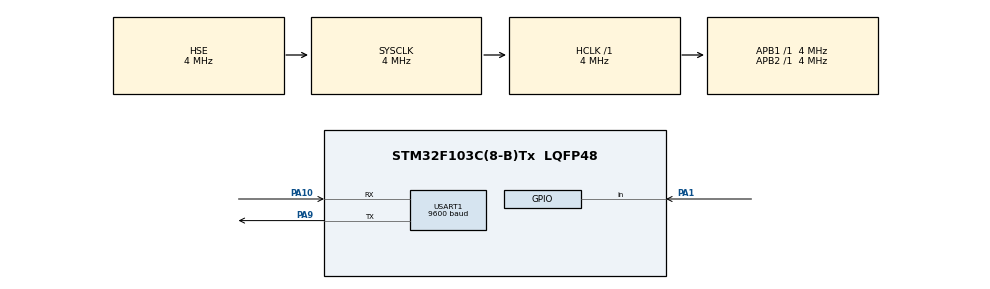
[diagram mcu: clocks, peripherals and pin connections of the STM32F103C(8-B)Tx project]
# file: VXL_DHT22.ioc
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Mcu.Family=STM32F1
Mcu.Name=STM32F103C(8-B)Tx
Mcu.Package=LQFP48
NVIC.PriorityGroup=NVIC_PRIORITYGROUP_4
PA1.GPIO_PuPd=GPIO_PULLUP
PA1.Signal=GPIO_Input
PA10.Mode=Asynchronous
PA10.Signal=USART1_RX
PA13.Mode=Serial_Wire
PA13.Signal=SYS_JTMS-SWDIO
PA14.Mode=Serial_Wire
PA14.Signal=SYS_JTCK-SWCLK
PA9.Mode=Asynchronous
PA9.Signal=USART1_TX
PD0-OSC_IN.Mode=HSE-External-Oscillator
PD0-OSC_IN.Signal=RCC_OSC_IN
PD1-OSC_OUT.Mode=HSE-External-Oscillator
PD1-OSC_OUT.Signal=RCC_OSC_OUT
ProjectManager.HeapSize=0x200
ProjectManager.StackSize=0x400
ProjectManager.TargetToolchain=MDK-ARM V5.32
RCC.AHBFreq_Value=4000000
RCC.APB1Freq_Value=4000000
RCC.APB1TimFreq_Value=4000000
RCC.APB2Freq_Value=4000000
RCC.APB2TimFreq_Value=4000000
RCC.HCLKFreq_Value=4000000
RCC.HSE_VALUE=4000000
RCC.SYSCLKFreq_VALUE=4000000
RCC.SYSCLKSource=RCC_SYSCLKSOURCE_HSE
USART1.BaudRate=9600
USART1.VirtualMode=VM_ASYNC
VP_TIM1_VS_ClockSourceINT.Mode=Internal
board=custom

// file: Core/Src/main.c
/* USER CODE BEGIN Header */
/**
  ******************************************************************************
  * @file           : main.c
  * @brief          : Main program body
  ******************************************************************************
  * @attention
  *
  * Copyright (c) 2023 STMicroelectronics.
  * All rights reserved.
  *
  * This software is licensed under terms that can be found in the LICENSE file
  * in the root directory of this software component.
  * If no LICENSE file comes with this software, it is provided AS-IS.
  *
  ******************************************************************************
  */
/* USER CODE END Header */
#include "main.h"

/* USER CODE BEGIN Includes */
#include <stdio.h>
/*struct __FILE
{
  int handle;
};*/
/* USER CODE END Includes */

TIM_HandleTypeDef htim1;

UART_HandleTypeDef huart1;

/* USER CODE BEGIN PV */
FILE __stdout;
int fputc(int ch, FILE *f)
{
  HAL_UART_Transmit(&huart1,(uint8_t *)&ch,1,HAL_MAX_DELAY);
  return ch;
}
/* USER CODE END PV */

void SystemClock_Config(void);
static void MX_GPIO_Init(void);
static void MX_TIM1_Init(void);
static void MX_USART1_UART_Init(void);

/* USER CODE BEGIN 0 */
uint8_t OneWire_ReadBit(void) {
	#define DELAY50US  200
	while(HAL_GPIO_ReadPin(GPIOA,GPIO_PIN_1)==0);
	__HAL_TIM_SET_COUNTER(&htim1,0);
	while(HAL_GPIO_ReadPin(GPIOA,GPIO_PIN_1)!=0);
	if (__HAL_TIM_GET_COUNTER(&htim1) > DELAY50US)
		return 1;
	else
		return 0;
}

/* USER CODE END 0 */

int main(void)
{

  /* MCU Configuration--------------------------------------------------------*/

  /* Reset of all peripherals, Initializes the Flash interface and the Systick. */
  HAL_Init();

  /* Configure the system clock */
  SystemClock_Config();

  /* Initialize all configured peripherals */
  MX_GPIO_Init();
  MX_TIM1_Init();
  MX_USART1_UART_Init();
  /* USER CODE BEGIN 2 */
	HAL_TIM_Base_Start(&htim1);
	GPIO_InitTypeDef GPIO_InitStruct = {0};
  /* USER CODE END 2 */

  /* Infinite loop */
  while (1)
  {
		/*Configure GPIO pin : PA1 */ // pull_up
			GPIO_InitStruct.Pin = GPIO_PIN_1;
			GPIO_InitStruct.Mode = GPIO_MODE_OUTPUT_PP;
			GPIO_InitStruct.Pull = GPIO_PULLUP;
		  GPIO_InitStruct.Speed = GPIO_SPEED_FREQ_LOW;
			HAL_GPIO_Init(GPIOA, &GPIO_InitStruct);
			HAL_GPIO_WritePin(GPIOA,GPIO_PIN_1,GPIO_PIN_RESET);
			HAL_Delay(19);

			GPIO_InitStruct.Pin = GPIO_PIN_1;
			GPIO_InitStruct.Mode = GPIO_MODE_INPUT;
			GPIO_InitStruct.Pull = GPIO_PULLUP;
			HAL_GPIO_Init(GPIOA, &GPIO_InitStruct);
			while(HAL_GPIO_ReadPin(GPIOA,GPIO_PIN_1)!=0);
			while(HAL_GPIO_ReadPin(GPIOA,GPIO_PIN_1)==0);
			while(HAL_GPIO_ReadPin(GPIOA,GPIO_PIN_1)!=0);

			uint8_t DHT_Data[] = {0, 0, 0, 0, 0};
			float humidity, temperature;

			for (uint8_t i = 0; i < 5; i++) {
					for (uint8_t j = 0; j < 8; j++) {
							DHT_Data[i] = DHT_Data[i] | (OneWire_ReadBit() << (7 - j));
					}
			}

			humidity = (float)(DHT_Data[0] << 8 | DHT_Data[1])*0.1;
			temperature = (float)(DHT_Data[2] << 8 | DHT_Data[3])*0.1;

			printf("RH = %.1f ; T = %.1f     ", humidity, temperature);
			HAL_Delay(500);

  }
}

void SystemClock_Config(void)
{
  RCC_OscInitTypeDef RCC_OscInitStruct = {0};
  RCC_ClkInitTypeDef RCC_ClkInitStruct = {0};

  /** Initializes the RCC Oscillators according to the specified parameters
  * in the RCC_OscInitTypeDef structure.
  */
  RCC_OscInitStruct.OscillatorType = RCC_OSCILLATORTYPE_HSE;
  RCC_OscInitStruct.HSEState = RCC_HSE_ON;
  RCC_OscInitStruct.PLL.PLLState = RCC_PLL_NONE;
  if (HAL_RCC_OscConfig(&RCC_OscInitStruct) != HAL_OK)
  {
    Error_Handler();
  }

  /** Initializes the CPU, AHB and APB buses clocks
  */
  RCC_ClkInitStruct.ClockType = RCC_CLOCKTYPE_HCLK|RCC_CLOCKTYPE_SYSCLK
                              |RCC_CLOCKTYPE_PCLK1|RCC_CLOCKTYPE_PCLK2;
  RCC_ClkInitStruct.SYSCLKSource = RCC_SYSCLKSOURCE_HSE;
  RCC_ClkInitStruct.AHBCLKDivider = RCC_SYSCLK_DIV1;
  RCC_ClkInitStruct.APB1CLKDivider = RCC_HCLK_DIV1;
  RCC_ClkInitStruct.APB2CLKDivider = RCC_HCLK_DIV1;

  if (HAL_RCC_ClockConfig(&RCC_ClkInitStruct, FLASH_LATENCY_0) != HAL_OK)
  {
    Error_Handler();
  }
}

static void MX_TIM1_Init(void)
{

  TIM_ClockConfigTypeDef sClockSourceConfig = {0};
  TIM_MasterConfigTypeDef sMasterConfig = {0};

  htim1.Instance = TIM1;
  htim1.Init.Prescaler = 0;
  htim1.Init.CounterMode = TIM_COUNTERMODE_UP;
  htim1.Init.Period = 65535;
  htim1.Init.ClockDivision = TIM_CLOCKDIVISION_DIV1;
  htim1.Init.RepetitionCounter = 0;
  htim1.Init.AutoReloadPreload = TIM_AUTORELOAD_PRELOAD_DISABLE;
  if (HAL_TIM_Base_Init(&htim1) != HAL_OK)
  {
    Error_Handler();
  }
  sClockSourceConfig.ClockSource = TIM_CLOCKSOURCE_INTERNAL;
  if (HAL_TIM_ConfigClockSource(&htim1, &sClockSourceConfig) != HAL_OK)
  {
    Error_Handler();
  }
  sMasterConfig.MasterOutputTrigger = TIM_TRGO_RESET;
  sMasterConfig.MasterSlaveMode = TIM_MASTERSLAVEMODE_DISABLE;
  if (HAL_TIMEx_MasterConfigSynchronization(&htim1, &sMasterConfig) != HAL_OK)
  {
    Error_Handler();
  }

}

static void MX_USART1_UART_Init(void)
{

  huart1.Instance = USART1;
  huart1.Init.BaudRate = 9600;
  huart1.Init.WordLength = UART_WORDLENGTH_8B;
  huart1.Init.StopBits = UART_STOPBITS_1;
  huart1.Init.Parity = UART_PARITY_NONE;
  huart1.Init.Mode = UART_MODE_TX_RX;
  huart1.Init.HwFlowCtl = UART_HWCONTROL_NONE;
  huart1.Init.OverSampling = UART_OVERSAMPLING_16;
  if (HAL_UART_Init(&huart1) != HAL_OK)
  {
    Error_Handler();
  }

}

static void MX_GPIO_Init(void)
{
  GPIO_InitTypeDef GPIO_InitStruct = {0};

  /* GPIO Ports Clock Enable */
  __HAL_RCC_GPIOC_CLK_ENABLE();
  __HAL_RCC_GPIOD_CLK_ENABLE();
  __HAL_RCC_GPIOA_CLK_ENABLE();
  __HAL_RCC_GPIOB_CLK_ENABLE();

  /*Configure GPIO pins : PC13 PC14 PC15 */
  GPIO_InitStruct.Pin = GPIO_PIN_13|GPIO_PIN_14|GPIO_PIN_15;
  GPIO_InitStruct.Mode = GPIO_MODE_ANALOG;
  HAL_GPIO_Init(GPIOC, &GPIO_InitStruct);

  /*Configure GPIO pins : PA0 PA2 PA3 PA4
                           PA5 PA6 PA7 PA8
                           PA11 PA12 PA15 */
  GPIO_InitStruct.Pin = GPIO_PIN_0|GPIO_PIN_2|GPIO_PIN_3|GPIO_PIN_4
                          |GPIO_PIN_5|GPIO_PIN_6|GPIO_PIN_7|GPIO_PIN_8
                          |GPIO_PIN_11|GPIO_PIN_12|GPIO_PIN_15;
  GPIO_InitStruct.Mode = GPIO_MODE_ANALOG;
  HAL_GPIO_Init(GPIOA, &GPIO_InitStruct);

  /*Configure GPIO pin : PA1 */
  GPIO_InitStruct.Pin = GPIO_PIN_1;
  GPIO_InitStruct.Mode = GPIO_MODE_INPUT;
  GPIO_InitStruct.Pull = GPIO_PULLUP;
  HAL_GPIO_Init(GPIOA, &GPIO_InitStruct);

  /*Configure GPIO pins : PB0 PB1 PB2 PB10
                           PB11 PB12 PB13 PB14
                           PB15 PB3 PB4 PB5
                           PB6 PB7 PB8 PB9 */
  GPIO_InitStruct.Pin = GPIO_PIN_0|GPIO_PIN_1|GPIO_PIN_2|GPIO_PIN_10
                          |GPIO_PIN_11|GPIO_PIN_12|GPIO_PIN_13|GPIO_PIN_14
                          |GPIO_PIN_15|GPIO_PIN_3|GPIO_PIN_4|GPIO_PIN_5
                          |GPIO_PIN_6|GPIO_PIN_7|GPIO_PIN_8|GPIO_PIN_9;
  GPIO_InitStruct.Mode = GPIO_MODE_ANALOG;
  HAL_GPIO_Init(GPIOB, &GPIO_InitStruct);

}

void Error_Handler(void)
{
  __disable_irq();
  while (1)
  {
  }
}
